# ESP32-H21 register map
Vendor: ESPRESSIF SYSTEMS (SHANGHAI) CO., LTD.; Series: ESP32 H-Series; File version: 1
CPU: RV32IMAC r0p0, little endian, no MPU, no FPU, 0 interrupt priority bits
Address unit: 32 bits
Registers are 32-bit, read-write, reset 0x0 unless marked. A register's access mark holds for its fields unless they carry their own. Offsets are from the block's base; [hi:lo] are bit positions.

## HP_SYS — High-Power System
Base 0x60095000
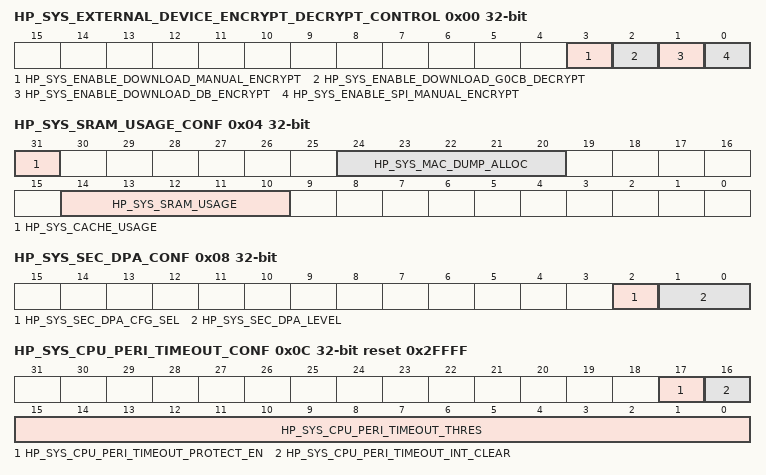
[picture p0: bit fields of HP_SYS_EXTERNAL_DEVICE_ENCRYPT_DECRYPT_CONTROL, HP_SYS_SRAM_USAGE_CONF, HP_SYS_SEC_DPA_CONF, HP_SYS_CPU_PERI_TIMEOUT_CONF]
0x00 HP_SYS_EXTERNAL_DEVICE_ENCRYPT_DECRYPT_CONTROL access per field — EXTERNAL DEVICE ENCRYPTION/DECRYPTION configuration register
  [3] HP_SYS_ENABLE_DOWNLOAD_MANUAL_ENCRYPT rw — Set this bit as 1 to enable mspi xts manual encrypt in download boot mode.
  [2] HP_SYS_ENABLE_DOWNLOAD_G0CB_DECRYPT rw — Set this bit as 1 to enable mspi xts auto decrypt in download boot mode.
  [1] HP_SYS_ENABLE_DOWNLOAD_DB_ENCRYPT ro — reserved
  [0] HP_SYS_ENABLE_SPI_MANUAL_ENCRYPT rw — Set this bit as 1 to enable mspi xts manual encrypt in spi boot mode.
0x04 HP_SYS_SRAM_USAGE_CONF access per field — HP memory usage configuration register
  [31] HP_SYS_CACHE_USAGE ro — reserved
  [24:20] HP_SYS_MAC_DUMP_ALLOC rw — reserved.
  [14:10] HP_SYS_SRAM_USAGE rw — 0: cpu use hp-memory. 1: mac-dump accessing hp-memory.
0x08 HP_SYS_SEC_DPA_CONF — HP anti-DPA security configuration register
  [2] HP_SYS_SEC_DPA_CFG_SEL — This field is used to select either HP_SYS_SEC_DPA_LEVEL or EFUSE_SEC_DPA_LEVEL (from efuse) to control dpa_level. 0: EFUSE_SEC_DPA_LEVEL, 1: HP_SYS_SEC_DPA_LEVEL.
  [1:0] HP_SYS_SEC_DPA_LEVEL — 0: anti-DPA disable. 1~3: anti-DPA enable with different security level. The larger the number, the stronger the ability to resist DPA attacks and the higher the security level, but it will increase the computational overhead of the hardware crypto-accelerators. Only avaliable if HP_SYS_SEC_DPA_CFG_SEL is 0.
0x0C HP_SYS_CPU_PERI_TIMEOUT_CONF access per field reset 0x2FFFF — CPU_PERI_TIMEOUT configuration register
  [17] HP_SYS_CPU_PERI_TIMEOUT_PROTECT_EN rw — Set this bit as 1 to enable timeout protection for accessing cpu peripheral registers
  [16] HP_SYS_CPU_PERI_TIMEOUT_INT_CLEAR wo — Set this bit as 1 to clear timeout interrupt
  [15:0] HP_SYS_CPU_PERI_TIMEOUT_THRES rw — Set the timeout threshold for bus access, corresponding to the number of clock cycles of the clock domain.
0x10 HP_SYS_CPU_PERI_TIMEOUT_ADDR ro — CPU_PERI_TIMEOUT_ADDR register
  [31:0] HP_SYS_CPU_PERI_TIMEOUT_ADDR — Record the address information of abnormal access
0x14 HP_SYS_CPU_PERI_TIMEOUT_UID ro — CPU_PERI_TIMEOUT_UID register
  [6:0] HP_SYS_CPU_PERI_TIMEOUT_UID — Record master id[4:0] & master permission[6:5] when trigger timeout. This register will be cleared after the interrupt is cleared.
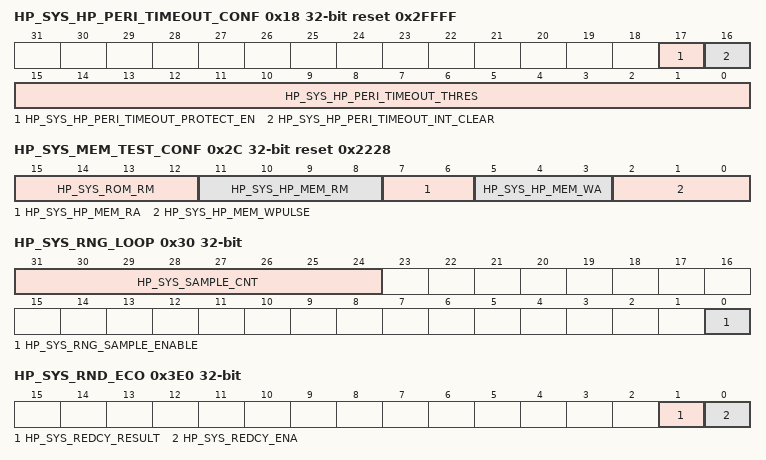
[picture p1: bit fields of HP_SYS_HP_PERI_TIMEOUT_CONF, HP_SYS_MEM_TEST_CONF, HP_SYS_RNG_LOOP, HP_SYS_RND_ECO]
0x18 HP_SYS_HP_PERI_TIMEOUT_CONF access per field reset 0x2FFFF — HP_PERI_TIMEOUT configuration register
  [17] HP_SYS_HP_PERI_TIMEOUT_PROTECT_EN rw — Set this bit as 1 to enable timeout protection for accessing hp peripheral registers
  [16] HP_SYS_HP_PERI_TIMEOUT_INT_CLEAR wo — Set this bit as 1 to clear timeout interrupt
  [15:0] HP_SYS_HP_PERI_TIMEOUT_THRES rw — Set the timeout threshold for bus access, corresponding to the number of clock cycles of the clock domain.
0x1C HP_SYS_HP_PERI_TIMEOUT_ADDR ro — HP_PERI_TIMEOUT_ADDR register
  [31:0] HP_SYS_HP_PERI_TIMEOUT_ADDR — Record the address information of abnormal access
0x20 HP_SYS_HP_PERI_TIMEOUT_UID ro — HP_PERI_TIMEOUT_UID register
  [6:0] HP_SYS_HP_PERI_TIMEOUT_UID — Record master id[4:0] & master permission[6:5] when trigger timeout. This register will be cleared after the interrupt is cleared.
0x24 HP_SYS_ROM_TABLE_LOCK — Rom-Table lock register
  [0] HP_SYS_ROM_TABLE_LOCK — XXXX
0x28 HP_SYS_ROM_TABLE — Rom-Table register
  [31:0] HP_SYS_ROM_TABLE — XXXX
0x2C HP_SYS_MEM_TEST_CONF reset 0x2228 — MEM_TEST configuration register
  [15:12] HP_SYS_ROM_RM — This field controls rom RM parameter. 0b0011 for 1.1V operating Voltage, 0b0010 for 1.0V, 0b0010(default) or 0b0001(slow) for 0.9V.
  [11:8] HP_SYS_HP_MEM_RM — This field controls hp system memory RM parameter. 0b0011 for 1.1V operating Voltage, 0b0010 for 1.0V, 0b0000 for 0.9V.
  [7:6] HP_SYS_HP_MEM_RA — This field controls hp system memory RA parameter. 0b00 for 1.1V/1.0V operating Voltage, 0b01 for 0.9V.
  [5:3] HP_SYS_HP_MEM_WA — This field controls hp system memory WA parameter. 0b100 for 1.1V operating Voltage, 0b101 for 1.0V, 0b110 for 0.9V.
  [2:0] HP_SYS_HP_MEM_WPULSE — This field controls hp system memory WPULSE parameter. 0b000 for 1.1V/1.0V/0.9V operating Voltage.
0x30 HP_SYS_RNG_LOOP access per field — configure rng_ring
  [31:24] HP_SYS_SAMPLE_CNT ro — This field get rng ring count
  [0] HP_SYS_RNG_SAMPLE_ENABLE rw — enable rng digital ring count
0x34 HP_SYS_CACHE_MEM_CLK_FO — debug
  [0] CACHE_MEM_CLK_FO
0x3E0 HP_SYS_RND_ECO access per field — redcy eco register.
  [1] HP_SYS_REDCY_RESULT ro — Only reserved for ECO.
  [0] HP_SYS_REDCY_ENA rw — Only reserved for ECO.
0x3E4 HP_SYS_RND_ECO_LOW — redcy eco low register.
  [31:0] HP_SYS_REDCY_LOW — Only reserved for ECO.
0x3E8 HP_SYS_RND_ECO_HIGH reset 0xFFFFFFFF — redcy eco high register.
  [31:0] HP_SYS_REDCY_HIGH — Only reserved for ECO.
0x3F4 HP_SYS_DEBUG reset 0x1 — HP-SYSTEM debug register
  [0] HP_SYS_FPGA_DEBUG — Reserved
0x3F8 HP_SYS_CLOCK_GATE — HP-SYSTEM clock gating configure register
  [0] HP_SYS_CLK_EN — Set this bit as 1 to force on clock gating.
0x3FC HP_SYS_DATE reset 0x2408270 — Date register.
  [27:0] HP_SYS_DATE — HP-SYSTEM date information/ HP-SYSTEM version information.
